AUTOSAR XML (schema 00045)
package /LcfAdapter
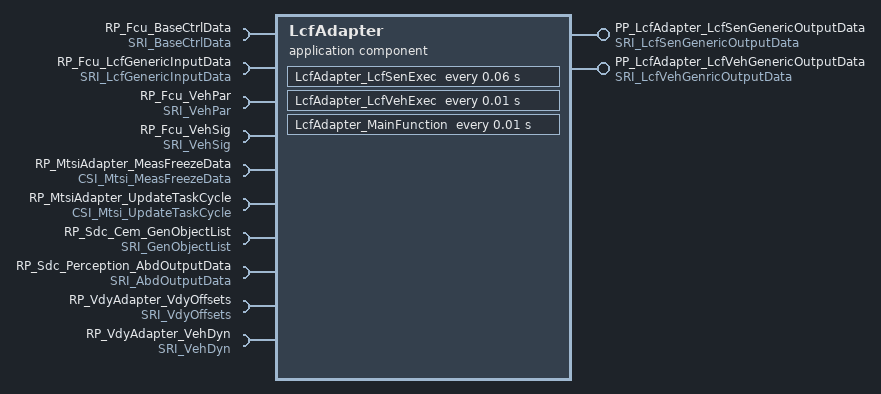
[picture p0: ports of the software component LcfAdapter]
  application sw component type LcfAdapter
    provide port PP_LcfAdapter_LcfSenGenericOutputData: provided-interface=SRI_LcfSenGenericOutputData
    provide port PP_LcfAdapter_LcfVehGenericOutputData: provided-interface=SRI_LcfVehGenricOutputData
    10 x require port:
      RP_Fcu_BaseCtrlData: required-interface=SRI_BaseCtrlData
      RP_Fcu_LcfGenericInputData: required-interface=SRI_LcfGenericInputData
      RP_Fcu_VehPar: required-interface=SRI_VehPar
      RP_Fcu_VehSig: required-interface=SRI_VehSig
      RP_MtsiAdapter_MeasFreezeData: required-interface=CSI_Mtsi_MeasFreezeData
      RP_MtsiAdapter_UpdateTaskCycle: required-interface=CSI_Mtsi_UpdateTaskCycle
      RP_Sdc_Cem_GenObjectList: required-interface=SRI_GenObjectList
      RP_Sdc_Perception_AbdOutputData: required-interface=SRI_AbdOutputData
      RP_VdyAdapter_VdyOffsets: required-interface=SRI_VdyOffsets
      RP_VdyAdapter_VehDyn: required-interface=SRI_VehDyn
    behavior LcfAdapter_IB: handle-termination-and-restart=NO-SUPPORT
      init event InitEvent_LcfAdapter_InitFunction: start-on-event=LcfAdapter_InitFunction
      timing event TimingEvent_LcfAdapter_LcfSenExec: start-on-event=LcfAdapter_LcfSenExec, period=0.06
      timing event TimingEvent_LcfAdapter_LcfVehExec: start-on-event=LcfAdapter_LcfVehExec, period=0.01
      timing event TimingEvent_LcfAdapter_MainFunction: start-on-event=LcfAdapter_MainFunction, period=0.01
      4 x runnable:
        LcfAdapter_InitFunction
          data-receive-point-by-arguments:
            8 x access:
              drparg_AbdOutputData_t: accessed-variable=RP_Sdc_Perception_AbdOutputData.AbdOutputData_t
              drparg_BaseCtrlData: accessed-variable=RP_Fcu_BaseCtrlData.BaseCtrlData
              drparg_GenObjectList: accessed-variable=RP_Sdc_Cem_GenObjectList.GenObjectList
              drparg_LcfGenericInputData: accessed-variable=RP_Fcu_LcfGenericInputData.LcfGenericInputData
              drparg_VdyOffsets: accessed-variable=RP_VdyAdapter_VdyOffsets.VdyOffsets
              drparg_VehDyn: accessed-variable=RP_VdyAdapter_VehDyn.VehDyn
              drparg_VehPar: accessed-variable=RP_Fcu_VehPar.VehPar
              drparg_VehSig: accessed-variable=RP_Fcu_VehSig.VehSig
          data-send-points:
            access dsp_LcfSenGenericOutputData: accessed-variable=PP_LcfAdapter_LcfSenGenericOutputData.LcfSenGenericOutputData
            access dsp_LcfVehGenericOutputData: accessed-variable=PP_LcfAdapter_LcfVehGenericOutputData.LcfVehGenricOutputData
        LcfAdapter_LcfSenExec
          data-receive-point-by-arguments:
            8 x access:
              drparg_AbdOutputData_t: accessed-variable=RP_Sdc_Perception_AbdOutputData.AbdOutputData_t
              drparg_BaseCtrlData: accessed-variable=RP_Fcu_BaseCtrlData.BaseCtrlData
              drparg_GenObjectList: accessed-variable=RP_Sdc_Cem_GenObjectList.GenObjectList
              drparg_LcfGenericInputData: accessed-variable=RP_Fcu_LcfGenericInputData.LcfGenericInputData
              drparg_VdyOffsets: accessed-variable=RP_VdyAdapter_VdyOffsets.VdyOffsets
              drparg_VehDyn: accessed-variable=RP_VdyAdapter_VehDyn.VehDyn
              drparg_VehPar: accessed-variable=RP_Fcu_VehPar.VehPar
              drparg_VehSig: accessed-variable=RP_Fcu_VehSig.VehSig
          data-send-points:
            access dsp_LcfSenGenericOutputData: accessed-variable=PP_LcfAdapter_LcfSenGenericOutputData.LcfSenGenericOutputData
            access dsp_LcfVehGenericOutputData: accessed-variable=PP_LcfAdapter_LcfVehGenericOutputData.LcfVehGenricOutputData
        LcfAdapter_LcfVehExec
          data-receive-point-by-arguments:
            8 x access:
              drparg_AbdOutputData_t: accessed-variable=RP_Sdc_Perception_AbdOutputData.AbdOutputData_t
              drparg_BaseCtrlData: accessed-variable=RP_Fcu_BaseCtrlData.BaseCtrlData
              drparg_GenObjectList: accessed-variable=RP_Sdc_Cem_GenObjectList.GenObjectList
              drparg_LcfGenericInputData: accessed-variable=RP_Fcu_LcfGenericInputData.LcfGenericInputData
              drparg_VdyOffsets: accessed-variable=RP_VdyAdapter_VdyOffsets.VdyOffsets
              drparg_VehDyn: accessed-variable=RP_VdyAdapter_VehDyn.VehDyn
              drparg_VehPar: accessed-variable=RP_Fcu_VehPar.VehPar
              drparg_VehSig: accessed-variable=RP_Fcu_VehSig.VehSig
          data-send-points:
            access dsp_LcfSenGenericOutputData: accessed-variable=PP_LcfAdapter_LcfSenGenericOutputData.LcfSenGenericOutputData
            access dsp_LcfVehGenericOutputData: accessed-variable=PP_LcfAdapter_LcfVehGenericOutputData.LcfVehGenricOutputData
        LcfAdapter_MainFunction
          data-receive-point-by-arguments:
            8 x access:
              drparg_AbdOutputData_t: accessed-variable=RP_Sdc_Perception_AbdOutputData.AbdOutputData_t
              drparg_BaseCtrlData: accessed-variable=RP_Fcu_BaseCtrlData.BaseCtrlData
              drparg_GenObjectList: accessed-variable=RP_Sdc_Cem_GenObjectList.GenObjectList
              drparg_LcfGenericInputData: accessed-variable=RP_Fcu_LcfGenericInputData.LcfGenericInputData
              drparg_VdyOffsets: accessed-variable=RP_VdyAdapter_VdyOffsets.VdyOffsets
              drparg_VehDyn: accessed-variable=RP_VdyAdapter_VehDyn.VehDyn
              drparg_VehPar: accessed-variable=RP_Fcu_VehPar.VehPar
              drparg_VehSig: accessed-variable=RP_Fcu_VehSig.VehSig
          data-send-points:
            access dsp_LcfSenGenericOutputData: accessed-variable=PP_LcfAdapter_LcfSenGenericOutputData.LcfSenGenericOutputData
            access dsp_LcfVehGenericOutputData: accessed-variable=PP_LcfAdapter_LcfVehGenericOutputData.LcfVehGenricOutputData
          sync call scp_MeasFreezeData: operation=RP_MtsiAdapter_MeasFreezeData.MeasFreezeData, timeout=0.0
          sync call scp_UpdateTaskCycle: operation=RP_MtsiAdapter_UpdateTaskCycle.UpdateTaskCycle, timeout=0.0
  swc implementation LcfAdapterImpl: programming-language=C, sw-version=1.0.0, vendor-id=0, behavior=LcfAdapter_IB
    code-descriptors:
      code CodeGen: artifact-descriptors=[{short-label=SWHDR, category=SWHDR}, {short-label=SWSRC, category=SWSRC}]
    resource consumption Resource
      memory section CODE: sw-addrmethod=CODE
      memory section VAR_UNSPECIFIED: sw-addrmethod=VAR
